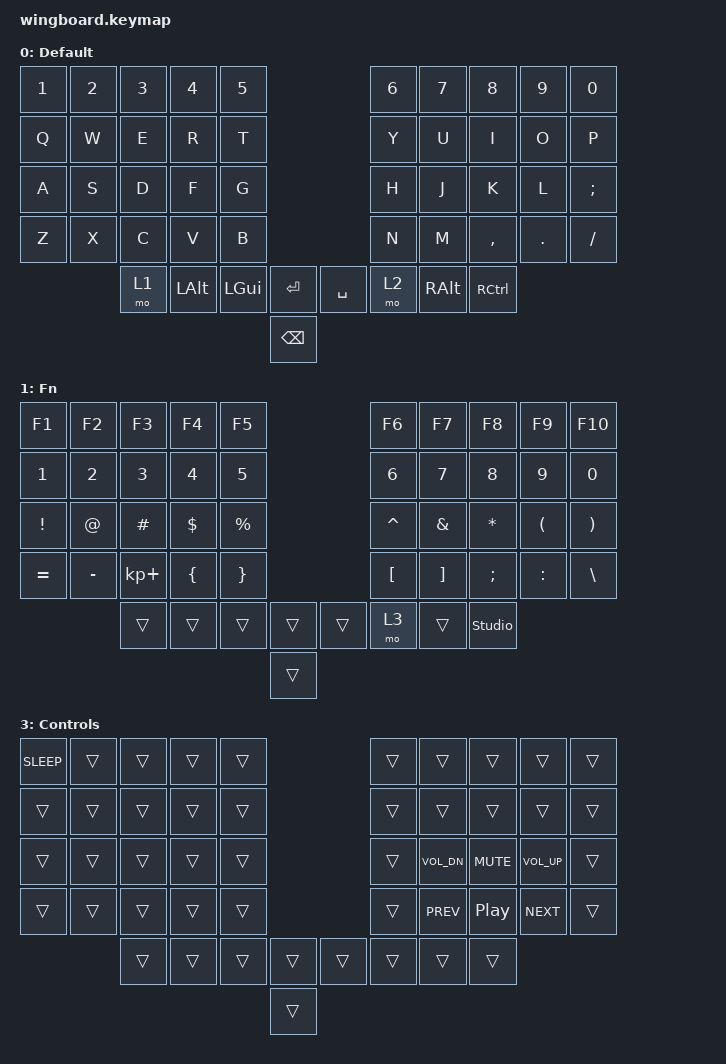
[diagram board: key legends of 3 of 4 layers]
#include <behaviors.dtsi>
#include <dt-bindings/zmk/keys.h>
#include <dt-bindings/zmk/bt.h>

/ {
    sensors: sensors {
        compatible = "zmk,keymap-sensors";
        sensors = <&center_encoder>;
        triggers-per-rotation = <20>;
    };

    keymap {
        compatible = "zmk,keymap";

        default_layer {
          // ,----------------------------------.               ,----------------------------------.
          // |  1   |  2   |  3   |  4   |  5   |               |  6   |  7   |  8   |  9   |  0   |
          // |------+------+------+------+------|               |------+------+------+------+------|
          // |  Q   |  W   |  E   |  R   |  T   |               |  Y   |  U   |  I   |  O   |  P   |
          // |------+------+------+------+------|               |------+------+------+------+------|
          // |  A   |  S   |  D   |  F   |  G   |               |  H   |  J   |  K   |  L   |  ;   |
          // |------+------+------+------+------.               |------+------+------+------+------|
          // |  Z   |  X   |  C   |  V   |  B   |               |  N   |  M   |  ,   |  .   |  /   |
          // `-------------+------+------+------+------. .------+------+------+------+------+------'
          //           | Function |      |      |      | |      | Actions |      |      |
          //           | layer MO | Alt  | Cmd  | ENTER| | SPACE| layer MO| Alt  | Ctrl |
          //           `----------------------------+--' '--+---------------------------'
          //                                        | BKSPC |                               
          //                                        '-------'
          bindings = <
            &kp N1 &kp N2    &kp N3   &kp N4   &kp N5                   &kp N6 &kp N7   &kp N8    &kp N9    &kp N0  
            &kp Q  &kp W     &kp E    &kp R    &kp T                    &kp Y  &kp U    &kp I     &kp O     &kp P   
            &kp A  &kp S     &kp D    &kp F    &kp G                    &kp H  &kp J    &kp K     &kp L     &kp SEMI
            &kp Z  &kp X     &kp C    &kp V    &kp B                    &kp N  &kp M    &kp COMMA &kp DOT   &kp FSLH
                             &mo 1  &kp LALT &kp LGUI &kp RET &kp SPACE &mo 2 &kp RALT  &kp RCTRL
                                                     &kp BSPC
          >;
          sensor-bindings = <&inc_dec_kp C_VOLUME_UP C_VOLUME_DOWN>;
          display-name = "Default";
        };

        function_layer {
          // ,----------------------------------.               ,----------------------------------.
          // |  F1  |  F2  |  F3  |  F4  |  F5  |               |  F6  |  F7  |  F8  |  F9  | F10  |
          // |------+------+------+------+------|               |------+------+------+------+------|
          // |  1   |  2   |  3   |  4   |  5   |               |  6   |  7   |  8   |  9   |  0   |
          // |------+------+------+------+------|               |------+------+------+------+------|
          // |  !   |  @   |  #   |  $   |  %   |               |  ^   |  &   |  *   |  (   |  )   |
          // |------+------+------+------+------.               |------+------+------+------+------|
          // |  =   |  -   |  +   |  {   |  }   |               |  [   |  ]   |  ;   |  :   |  \   |
          // `------+------+------+------+------+------. .------+------+------+------+------+------'
          //               |      |      |      |      | |      | Raise|      | Studio |
          //               |      |      |      |      | |      |      |      | Unlock |
          //               `------------------------+--' '--+--------------------------'
          //                                        |       |                               
          //                                        '-------'
          bindings = <
            &kp F1    &kp F2    &kp F3      &kp F4   &kp F5                 &kp F6    &kp F7   &kp F8    &kp F9    &kp F10 
            &kp N1    &kp N2    &kp N3      &kp N4   &kp N5                 &kp N6    &kp N7   &kp N8    &kp N9    &kp N0  
            &kp EXCL  &kp AT    &kp HASH    &kp DLLR &kp PRCNT              &kp CARET &kp AMPS &kp ASTRK &kp LPAR  &kp RPAR
            &kp EQUAL &kp MINUS &kp KP_PLUS &kp LBRC &kp RBRC               &kp LBKT  &kp RBKT &kp SEMI  &kp COLON &kp BSLH
                      &trans    &trans      &trans   &trans   &trans  &mo 3     &trans   &studio_unlock
                                                                  &trans
          >;
          sensor-bindings = <&inc_dec_kp PG_UP PG_DN>;
          display-name = "Fn";
        };

        actions_layer {
          // ,-----------------------------------------.               ,-----------------------------------------.
          // |BT CLR| BT1  | BT2  | BT3  | BT4  | BT5  |               |      |      |      |      |      |      |
          // |------+------+------+------+------+------|               |------+------+------+------+------+------|
          // |      | INS  | PSCRN| MENU |      | Scll |               | PG UP|      |  Up  |      |      | Del  |
          // |------+------+------+------+------+------|               |------+------+------+------+------+------|
          // |      |      |      |      |      | Caps |               | PG DN| Left | Down | Right|      |      |
          // |------+------+------+------+------+------+------. .------+------+------+------+------+------+------|
          // |      |      |      |      |      |      |      | |      |      | LStr |      | LEnd |      |      |
          // `-------------+------+------+------+------|      | |      |------+------+------+------+------+------'
          //               |      |      |      | Lower|      | |      |      |      |      |      |
          //               `-------------------------------+--' '--+-------------------------------'
          //                                               |       |                               
          //                                               '-------'
          bindings = <
            &bt BT_CLR &bt BT_SEL 0 &bt BT_SEL 1 &bt BT_SEL 2 &bt BT_SEL 3               &bt BT_SEL 4  &trans    &trans   &trans   &kp DEL 
            &kp INS    &kp PSCRN    &kp K_CMENU  &trans       &kp SLCK                   &kp PG_UP     &trans   &kp UP   &trans
            &trans     &trans       &trans       &trans       &kp CLCK                   &kp PG_DN     &kp LEFT &kp DOWN &kp RIGHT &trans 
            &trans     &trans       &trans       &trans       &trans                     &trans        &kp HOME &trans   &kp END   &trans 
                                    &trans       &trans       &trans       &mo 3  &trans &trans        &trans   &trans
                                                                              &trans
          >;
          sensor-bindings = <&inc_dec_kp C_VOLUME_UP C_VOLUME_DOWN>;
          display-name = "Actions";
        };

        controls_layer {
          // ,----------------------------------.               ,----------------------------------.
          // |      |      |      |      |      |               |      |      |      |      |      |
          // |------+------+------+------+------|               |------+------+------+------+------|
          // | RESET|      |      |      |      |               |      |      |      |      |      |
          // |------+------+------+------+------|               |------+------+------+------+------|
          // |      |      |      |      |      |               |      | VolDn| Mute | VolUp|      |
          // |------+------+------+------+------.               |------+------+------+------+------|
          // | MacSw|      |      |      |      |               |      | Prev | Play | Next | WinSw|
          // `-------------+------+------+------+------| |------+------+------+------+------+------'
          //               |      |      |      |      | |      |      |      |      |
          //               `------------------------+--' '--+------------------------'
          //                                        |       |                               
          //                                        '-------'
          bindings = <
              &kp K_SLEEP &trans &trans &trans &trans               &trans &trans       &trans     &trans       &trans
              &trans      &trans &trans &trans &trans               &trans &trans       &trans     &trans       &trans
              &trans      &trans &trans &trans &trans               &trans &kp C_VOL_DN &kp C_MUTE &kp C_VOL_UP &trans
              &trans      &trans &trans &trans &trans               &trans &kp C_PREV   &kp C_PP   &kp C_NEXT   &trans
                                 &trans &trans &trans &trans &trans &trans &trans       &trans
                                                         &trans
            >;
          display-name = "Controls";
        };

        additional_layer1 {
            status = "reserved";
        };

        additional_layer2 {
            status = "reserved";
        };
    };
};
